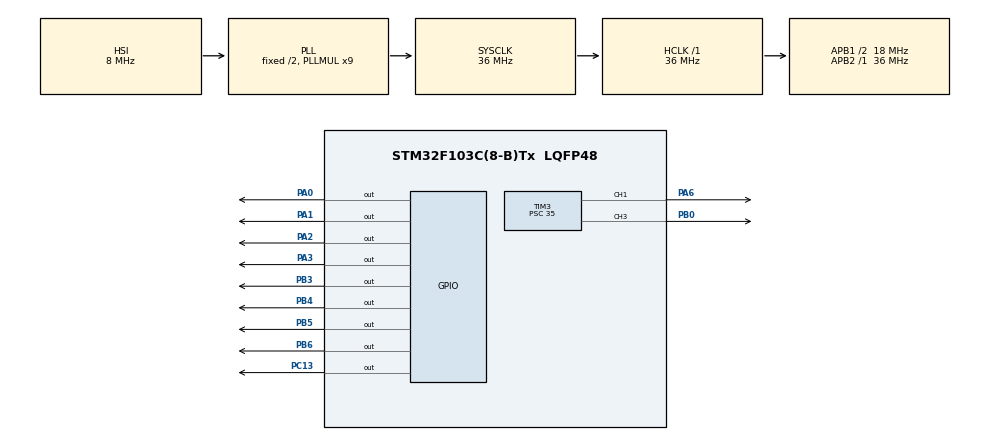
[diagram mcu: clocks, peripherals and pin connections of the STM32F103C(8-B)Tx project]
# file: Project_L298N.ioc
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Mcu.Family=STM32F1
Mcu.Name=STM32F103C(8-B)Tx
Mcu.Package=LQFP48
NVIC.PriorityGroup=NVIC_PRIORITYGROUP_4
PA0-WKUP.Signal=GPIO_Output
PA1.Signal=GPIO_Output
PA13.Mode=Serial_Wire
PA13.Signal=SYS_JTMS-SWDIO
PA14.Mode=Serial_Wire
PA14.Signal=SYS_JTCK-SWCLK
PA2.Signal=GPIO_Output
PA3.Signal=GPIO_Output
PA6.Signal=S_TIM3_CH1
PB0.Signal=S_TIM3_CH3
PB3.Signal=GPIO_Output
PB4.Signal=GPIO_Output
PB5.Signal=GPIO_Output
PB6.Signal=GPIO_Output
PC13-TAMPER-RTC.Signal=GPIO_Output
ProjectManager.HeapSize=0x200
ProjectManager.StackSize=0x400
ProjectManager.TargetToolchain=STM32CubeIDE
RCC.AHBFreq_Value=36000000
RCC.APB1CLKDivider=RCC_HCLK_DIV2
RCC.APB1Freq_Value=18000000
RCC.APB1TimFreq_Value=36000000
RCC.APB2Freq_Value=36000000
RCC.APB2TimFreq_Value=36000000
RCC.HCLKFreq_Value=36000000
RCC.PLLMUL=RCC_PLL_MUL9
RCC.SYSCLKFreq_VALUE=36000000
RCC.SYSCLKSource=RCC_SYSCLKSOURCE_PLLCLK
RCC.USBFreq_Value=36000000
SH.S_TIM3_CH1.0=TIM3_CH1,PWM Generation1 CH1
SH.S_TIM3_CH3.0=TIM3_CH3,PWM Generation3 CH3
TIM3.Channel-PWM\ Generation1\ CH1=TIM_CHANNEL_1
TIM3.Channel-PWM\ Generation3\ CH3=TIM_CHANNEL_3
TIM3.Period=999
TIM3.Prescaler=35
VP_TIM3_VS_ClockSourceINT.Mode=Internal
board=custom

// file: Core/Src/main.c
/* USER CODE BEGIN Header */
/**
  ******************************************************************************
  * @file           : main.c
  * @brief          : Main program body
  ******************************************************************************
  * @attention
  *
  * Copyright (c) 2022 STMicroelectronics.
  * All rights reserved.
  *
  * This software is licensed under terms that can be found in the LICENSE file
  * in the root directory of this software component.
  * If no LICENSE file comes with this software, it is provided AS-IS.
  *
  ******************************************************************************
  */
/* USER CODE END Header */
#include "main.h"

TIM_HandleTypeDef htim3;

void SystemClock_Config(void);
static void MX_GPIO_Init(void);
static void MX_TIM3_Init(void);

int main(void)
{

  /* MCU Configuration--------------------------------------------------------*/

  /* Reset of all peripherals, Initializes the Flash interface and the Systick. */
  HAL_Init();

  /* Configure the system clock */
  SystemClock_Config();

  /* Initialize all configured peripherals */
  MX_GPIO_Init();
  MX_TIM3_Init();
  /* USER CODE BEGIN 2 */
  HAL_TIM_PWM_Start(&htim3, TIM_CHANNEL_1);
  /* USER CODE END 2 */

  /* Infinite loop */
  while (1)
  {

    /* USER CODE BEGIN 3 */
//	  for(int i = 0;i<10000;i+=50)
//	  {
//		  __HAL_TIM_SET_COMPARE(&htim3,TIM_CHANNEL	_1,i);
//		     HAL_Delay(100);
//	  }
	  HAL_GPIO_WritePin(GPIOA, GPIO_PIN_0, 1);
	  HAL_GPIO_WritePin(GPIOA, GPIO_PIN_1, 0);
	  __HAL_TIM_SET_COMPARE(&htim3,TIM_CHANNEL_1,700);
  }
  /* USER CODE END 3 */
}

void SystemClock_Config(void)
{
  RCC_OscInitTypeDef RCC_OscInitStruct = {0};
  RCC_ClkInitTypeDef RCC_ClkInitStruct = {0};

  /** Initializes the RCC Oscillators according to the specified parameters
  * in the RCC_OscInitTypeDef structure.
  */
  RCC_OscInitStruct.OscillatorType = RCC_OSCILLATORTYPE_HSI;
  RCC_OscInitStruct.HSIState = RCC_HSI_ON;
  RCC_OscInitStruct.HSICalibrationValue = RCC_HSICALIBRATION_DEFAULT;
  RCC_OscInitStruct.PLL.PLLState = RCC_PLL_ON;
  RCC_OscInitStruct.PLL.PLLSource = RCC_PLLSOURCE_HSI_DIV2;
  RCC_OscInitStruct.PLL.PLLMUL = RCC_PLL_MUL9;
  if (HAL_RCC_OscConfig(&RCC_OscInitStruct) != HAL_OK)
  {
    Error_Handler();
  }

  /** Initializes the CPU, AHB and APB buses clocks
  */
  RCC_ClkInitStruct.ClockType = RCC_CLOCKTYPE_HCLK|RCC_CLOCKTYPE_SYSCLK
                              |RCC_CLOCKTYPE_PCLK1|RCC_CLOCKTYPE_PCLK2;
  RCC_ClkInitStruct.SYSCLKSource = RCC_SYSCLKSOURCE_PLLCLK;
  RCC_ClkInitStruct.AHBCLKDivider = RCC_SYSCLK_DIV1;
  RCC_ClkInitStruct.APB1CLKDivider = RCC_HCLK_DIV2;
  RCC_ClkInitStruct.APB2CLKDivider = RCC_HCLK_DIV1;

  if (HAL_RCC_ClockConfig(&RCC_ClkInitStruct, FLASH_LATENCY_1) != HAL_OK)
  {
    Error_Handler();
  }
}

static void MX_TIM3_Init(void)
{

  TIM_ClockConfigTypeDef sClockSourceConfig = {0};
  TIM_MasterConfigTypeDef sMasterConfig = {0};
  TIM_OC_InitTypeDef sConfigOC = {0};

  htim3.Instance = TIM3;
  htim3.Init.Prescaler = 35;
  htim3.Init.CounterMode = TIM_COUNTERMODE_UP;
  htim3.Init.Period = 999;
  htim3.Init.ClockDivision = TIM_CLOCKDIVISION_DIV1;
  htim3.Init.AutoReloadPreload = TIM_AUTORELOAD_PRELOAD_DISABLE;
  if (HAL_TIM_Base_Init(&htim3) != HAL_OK)
  {
    Error_Handler();
  }
  sClockSourceConfig.ClockSource = TIM_CLOCKSOURCE_INTERNAL;
  if (HAL_TIM_ConfigClockSource(&htim3, &sClockSourceConfig) != HAL_OK)
  {
    Error_Handler();
  }
  if (HAL_TIM_PWM_Init(&htim3) != HAL_OK)
  {
    Error_Handler();
  }
  sMasterConfig.MasterOutputTrigger = TIM_TRGO_RESET;
  sMasterConfig.MasterSlaveMode = TIM_MASTERSLAVEMODE_DISABLE;
  if (HAL_TIMEx_MasterConfigSynchronization(&htim3, &sMasterConfig) != HAL_OK)
  {
    Error_Handler();
  }
  sConfigOC.OCMode = TIM_OCMODE_PWM1;
  sConfigOC.Pulse = 0;
  sConfigOC.OCPolarity = TIM_OCPOLARITY_HIGH;
  sConfigOC.OCFastMode = TIM_OCFAST_DISABLE;
  if (HAL_TIM_PWM_ConfigChannel(&htim3, &sConfigOC, TIM_CHANNEL_1) != HAL_OK)
  {
    Error_Handler();
  }
  if (HAL_TIM_PWM_ConfigChannel(&htim3, &sConfigOC, TIM_CHANNEL_3) != HAL_OK)
  {
    Error_Handler();
  }
  HAL_TIM_MspPostInit(&htim3);

}

static void MX_GPIO_Init(void)
{
  GPIO_InitTypeDef GPIO_InitStruct = {0};

  /* GPIO Ports Clock Enable */
  __HAL_RCC_GPIOC_CLK_ENABLE();
  __HAL_RCC_GPIOA_CLK_ENABLE();
  __HAL_RCC_GPIOB_CLK_ENABLE();

  /*Configure GPIO pin Output Level */
  HAL_GPIO_WritePin(GPIOC, GPIO_PIN_13, GPIO_PIN_RESET);

  /*Configure GPIO pin Output Level */
  HAL_GPIO_WritePin(GPIOA, GPIO_PIN_0|GPIO_PIN_1|GPIO_PIN_2|GPIO_PIN_3, GPIO_PIN_RESET);

  /*Configure GPIO pin Output Level */
  HAL_GPIO_WritePin(GPIOB, GPIO_PIN_3|GPIO_PIN_4|GPIO_PIN_5|GPIO_PIN_6, GPIO_PIN_RESET);

  /*Configure GPIO pin : PC13 */
  GPIO_InitStruct.Pin = GPIO_PIN_13;
  GPIO_InitStruct.Mode = GPIO_MODE_OUTPUT_PP;
  GPIO_InitStruct.Pull = GPIO_NOPULL;
  GPIO_InitStruct.Speed = GPIO_SPEED_FREQ_LOW;
  HAL_GPIO_Init(GPIOC, &GPIO_InitStruct);

  /*Configure GPIO pins : PA0 PA1 PA2 PA3 */
  GPIO_InitStruct.Pin = GPIO_PIN_0|GPIO_PIN_1|GPIO_PIN_2|GPIO_PIN_3;
  GPIO_InitStruct.Mode = GPIO_MODE_OUTPUT_PP;
  GPIO_InitStruct.Pull = GPIO_NOPULL;
  GPIO_InitStruct.Speed = GPIO_SPEED_FREQ_LOW;
  HAL_GPIO_Init(GPIOA, &GPIO_InitStruct);

  /*Configure GPIO pins : PB3 PB4 PB5 PB6 */
  GPIO_InitStruct.Pin = GPIO_PIN_3|GPIO_PIN_4|GPIO_PIN_5|GPIO_PIN_6;
  GPIO_InitStruct.Mode = GPIO_MODE_OUTPUT_PP;
  GPIO_InitStruct.Pull = GPIO_NOPULL;
  GPIO_InitStruct.Speed = GPIO_SPEED_FREQ_LOW;
  HAL_GPIO_Init(GPIOB, &GPIO_InitStruct);

}

void Error_Handler(void)
{
  __disable_irq();
  while (1)
  {
  }
}
